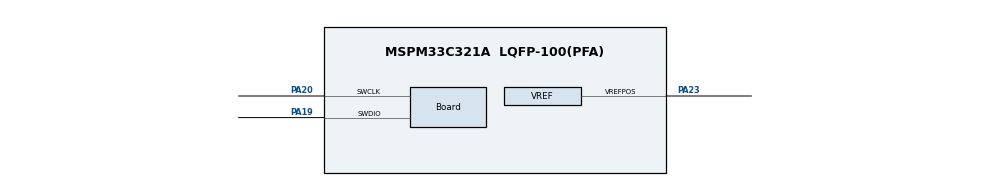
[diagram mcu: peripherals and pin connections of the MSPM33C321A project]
//@cliArgs --device "MSPM33C321A" --package "LQFP-100(PFA)" --part "Default"
//@v2CliArgs --device "MSPM33C321A" --package "LQFP-100(PFA)"
// @cliArgs --board /ti/boards/LP_MSPM33C321A --rtos nortos

/**
 * Import the modules used in this configuration.
 */
const Board         = scripting.addModule("/ti/driverlib/Board");
const CAPTURE       = scripting.addModule("/ti/driverlib/CAPTURE", {}, false);
const CAPTURE1      = CAPTURE.addInstance();
const COMP          = scripting.addModule("/ti/driverlib/COMP", {}, false);
const COMP1         = COMP.addInstance();
const SYSCTL        = scripting.addModule("/ti/driverlib/SYSCTL");
const VREF          = scripting.addModule("/ti/driverlib/VREF");
const ProjectConfig = scripting.addModule("/ti/project_config/ProjectConfig");

/**
 * Write custom configuration values to the imported modules.
 */
Board.InitPriority8               = "/ti/driverlib/VREF";
Board.peripheral.$assign          = "DEBUGSS";
Board.peripheral.swclkPin.$assign = "PA20";
Board.peripheral.swdioPin.$assign = "PA19";

CAPTURE1.$name              = "CAPTURE_0";
CAPTURE1.timerClkSrc        = "LFCLK";
CAPTURE1.timerClkDiv        = 2;
CAPTURE1.timerPeriod        = "2s";
CAPTURE1.captSelect         = "Trigger";
CAPTURE1.subscriberPort     = "FSUB0";
CAPTURE1.subscriberChannel  = 1;
CAPTURE1.interrupts         = ["CC0_DN","ZERO"];
CAPTURE1.peripheral.$assign = "TIMG4_0";

COMP1.$name                          = "COMP";
COMP1.selectOutputFilter             = "DL_COMP_FILTER_DELAY_1200";
COMP1.compMode                       = "DL_COMP_MODE_ULP";
COMP1.hysteresis                     = "DL_COMP_HYSTERESIS_30";
COMP1.vSource                        = "DL_COMP_REF_SOURCE_VDDA_DAC";
COMP1.controlSelect                  = "DL_COMP_DAC_CONTROL_SW";
COMP1.pubChanID                      = 1;
COMP1.enabledEvents                  = ["DL_COMP_EVENT_OUTPUT_EDGE"];
COMP1.channelEnable                  = ["NEG"];
COMP1.peripheral.$assign             = "COMP0";
COMP1.peripheral.compPinNeg0.$assign = "PA27";
COMP1.compPinNeg0Config.$name        = "ti_driverlib_gpio_GPIOPinGeneric0";

SYSCTL.powerPolicy        = "STOP";
SYSCTL.peripheral.$assign = "SYSCTL";

VREF.basicMode                     = "DL_VREF_ENABLE_ENABLE";
VREF.basicIntVolt                  = "DL_VREF_BUFCONFIG_OUTPUT_1_4V";
VREF.peripheral.$assign            = "VREF";
VREF.peripheral.vrefPosPin.$assign = "PA23";
VREF.vrefPosPinConfig.$name        = "ti_driverlib_gpio_GPIOPinGeneric1";

ProjectConfig.genLinker          = true;
ProjectConfig.genStartup         = true;
ProjectConfig.genLibs            = true;
ProjectConfig.genOpts            = true;
ProjectConfig.migrationCondition = true;
